# ESP32S31_RADIO register map
Vendor: Espressif; Series: ESP32-S31; File version: 3.52
Registers are 32-bit, read-write, no defined reset value unless marked. A register's access mark holds for its fields unless they carry their own. Offsets are from the block's base; [hi:lo] are bit positions.

## WIFI_MAC_RX_BSSID_LIST — Canonical WDEVRXCTR_BSSIDLIST word. Complete dbg_read_rx_misc names bits 19:18 RXCTL9_BSSID_POS; the HE init prefix independently writes encoding two to that same field.
Base 0x20104110
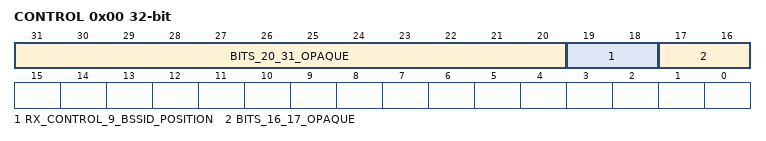
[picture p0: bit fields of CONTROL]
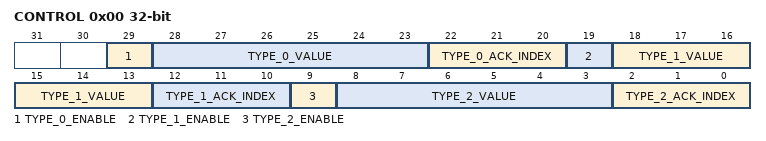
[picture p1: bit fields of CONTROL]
0x00 CONTROL — Project-assigned name.
  [31:20] BITS_20_31_OPAQUE — Opaque: meaning not established.
  [19:18] RX_CONTROL_9_BSSID_POSITION — Project-assigned name. Debug-decoded BSSID position field; complete hal_he_init writes encoding two.
  [17:16] BITS_16_17_OPAQUE — Opaque: meaning not established.

## WIFI_MAC_RX_CUSTOM_TYPE — WDEVTXRX_TAB three custom frame-type match and ACK-index profiles decoded by complete dbg_read_rx_misc.
Base 0x20104CA4
0x00 CONTROL — Project-assigned name.
  [29] TYPE_0_ENABLE — Project-assigned name.
  [28:23] TYPE_0_VALUE — Project-assigned name.
  [22:20] TYPE_0_ACK_INDEX — Project-assigned name.
  [19] TYPE_1_ENABLE — Project-assigned name.
  [18:13] TYPE_1_VALUE — Project-assigned name.
  [12:10] TYPE_1_ACK_INDEX — Project-assigned name.
  [9] TYPE_2_ENABLE — Project-assigned name.
  [8:3] TYPE_2_VALUE — Project-assigned name.
  [2:0] TYPE_2_ACK_INDEX — Project-assigned name.

## WIFI_MAC_RX_STATISTICS — Sparse RX hardware statistics decoded by complete dbg_read_rx_count. Ten-bit and sixteen-bit masks, the signed CFO transform and every register address below follow the complete instruction body and its pinned format string. Open HE HIL observed coherent MPDU/end/data, CFO, FCS, power-drop, HT-SIG, HE-SIG-A and interrupt counts while all buffer/FIFO/TKIP counters remained zero.
Base 0x2010430C
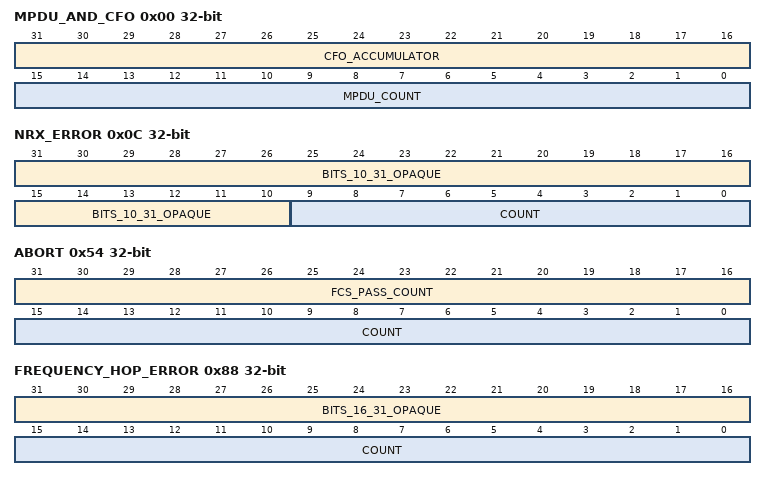
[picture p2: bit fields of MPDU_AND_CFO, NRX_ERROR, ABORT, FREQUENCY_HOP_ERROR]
0x00 MPDU_AND_CFO ro — Project-assigned name. WDEVRX_MPDU in bits 15:0. The blob sign-extends bits 31:16 and multiplies by 40 to print WDEVRX_CFO.
  [31:16] CFO_ACCUMULATOR — Project-assigned name.
  [15:0] MPDU_COUNT — Project-assigned name.
0x04 BRX_ERROR_AGC ro — Project-assigned name.
  [9:0] COUNT
0x08 BRX_ERROR ro — Project-assigned name.
  [9:0] COUNT
0x0C NRX_ERROR ro — Project-assigned name.
  [31:10] BITS_10_31_OPAQUE — Opaque: meaning not established. Observed source use; the individual hardware meaning is unknown.
  [9:0] COUNT — Project-assigned name.
0x10 NRX_ERROR_ABORT ro — Project-assigned name.
  [9:0] COUNT
0x14 NRX_ERROR_AGC_EXIT ro — Project-assigned name.
  [9:0] COUNT
0x18 NRX_ERROR_BASEBAND_OFF ro — Project-assigned name.
  [9:0] COUNT
0x1C NRX_ERROR_FDM_WATCHDOG ro — Project-assigned name.
  [9:0] COUNT
0x20 NRX_ERROR_POWER_DROP ro — Project-assigned name.
  [9:0] COUNT
0x24 NRX_ERROR_RESTART ro — Project-assigned name.
  [9:0] COUNT
0x28 NRX_ERROR_SERVICE ro — Project-assigned name.
  [9:0] COUNT
0x2C NRX_ERROR_TX_OVER ro — Project-assigned name.
  [9:0] COUNT
0x30 NRX_HE_UNSUPPORTED ro — Project-assigned name.
  [9:0] COUNT
0x34 NRX_HE_SIG_A_CRC ro — Project-assigned name.
  [9:0] COUNT
0x38 NRX_HE_FORMAT ro — Project-assigned name.
  [9:0] COUNT
0x3C NRX_HE_SIG_B_ERROR ro — Project-assigned name.
  [15:0] COUNT
0x40 NRX_HT_SIG_ERROR ro — Project-assigned name.
  [9:0] COUNT
0x44 NRX_UNSUPPORTED ro — Project-assigned name.
  [9:0] COUNT
0x50 SIGNAL_FIELD ro — Project-assigned name. WDEVRX_SF.
  [15:0] COUNT — Project-assigned name.
0x54 ABORT ro — Project-assigned name.
  [31:16] FCS_PASS_COUNT — Project-assigned name.
  [15:0] COUNT — Project-assigned name.
0x58 FCS_ERROR ro — Project-assigned name.
  [15:0] COUNT
0x5C FIFO_OVERFLOW ro — Project-assigned name.
  [15:0] COUNT
0x60 BUFFER_FULL ro — Project-assigned name.
  [15:0] COUNT
0x64 OTHER_UNICAST ro — Project-assigned name.
  [15:0] COUNT
0x68 TKIP_ERROR ro — Project-assigned name.
  [15:0] COUNT
0x6C SAME_BM_ERROR ro — Project-assigned name.
  [15:0] COUNT
0x70 ACK_INTERRUPT ro — Project-assigned name.
  [15:0] COUNT
0x74 RTS_INTERRUPT ro — Project-assigned name.
  [15:0] COUNT
0x78 CTS_INTERRUPT ro — Project-assigned name. Complete dbg_lmac_hw_statis_dump prints the full word at 0x20104384 as cts_int. Its internal field width is not inferred.
  [31:0] VALUE — Project-assigned name.
0x7C DATA_SUCCESS ro — Project-assigned name.
  [15:0] COUNT
0x80 END ro — Project-assigned name.
  [15:0] COUNT
0x84 BT_BLOCK_ERROR ro — Project-assigned name.
  [15:0] COUNT
0x88 FREQUENCY_HOP_ERROR ro — Project-assigned name.
  [31:16] BITS_16_31_OPAQUE — Opaque: meaning not established. Observed source use; the individual hardware meaning is unknown.
  [15:0] COUNT — Project-assigned name.
0x8C LAST_UNMATCHED_ERROR ro — Project-assigned name.
  [15:0] COUNT
0x90 TRIGGER ro — Project-assigned name. Complete dbg_lmac_hw_statis_dump prints the full word at 0x2010439c as trigger. This is a separate hardware-statistics observation from the decoded HE Trigger RX counter at 0x20104dbc.
  [31:0] VALUE — Project-assigned name.
